# ESP32S31_RADIO register map
Vendor: Espressif; Series: ESP32-S31; File version: 3.52
Registers are 32-bit, read-write, no defined reset value unless marked. A register's access mark holds for its fields unless they carry their own. Offsets are from the block's base; [hi:lo] are bit positions; {n}, {i} and the like mark numbered series; 'fields as' and 'values as' point back to an identical list.

## BT_V3_2_CTE — Bluetooth direction-finding control words recovered from complete, independently named CTE accessors in the ESP32-S31 vendor baseband library. Only fields touched by those accessors are described; untouched bits remain unassigned.
Base 0x20102000
0x94 LC_8M_CONTROL — Project-assigned name. Bluetooth CTE LC 8-Mbit enable control.
  [0] LC_8M_ENABLE — Project-assigned name. The matched getter/setter pair reads and replaces bit 0.
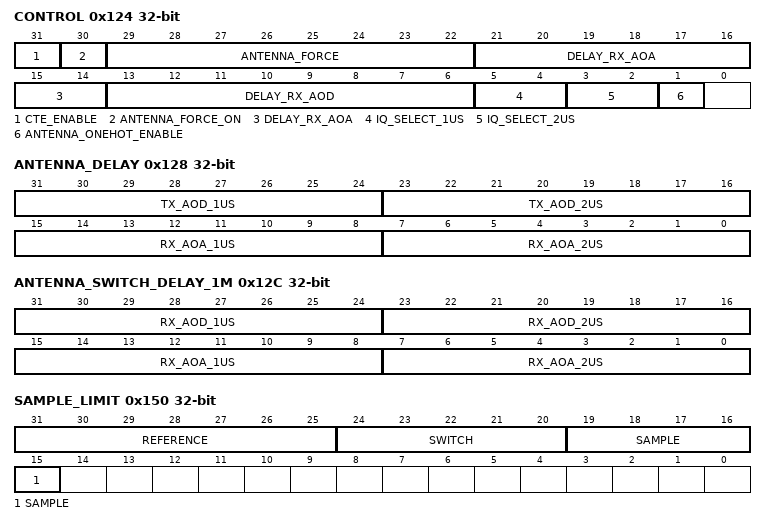
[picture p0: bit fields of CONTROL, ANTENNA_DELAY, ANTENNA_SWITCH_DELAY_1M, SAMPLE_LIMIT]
0x124 CONTROL — Project-assigned name. CTE antenna selection, receive-delay, IQ-selection and enable control. Bit 0 remains unassigned.
  [31] CTE_ENABLE — Project-assigned name. Complete ble_bb_cte_set_cte_en replaces bit 31 with the caller's Boolean image.
  [30] ANTENNA_FORCE_ON — Project-assigned name.
  [29:22] ANTENNA_FORCE — Project-assigned name.
  [21:14] DELAY_RX_AOA — Project-assigned name.
  [13:6] DELAY_RX_AOD — Project-assigned name.
  [5:4] IQ_SELECT_1US — Project-assigned name.
  [3:2] IQ_SELECT_2US — Project-assigned name.
  [1] ANTENNA_ONEHOT_ENABLE — Project-assigned name.
0x128 ANTENNA_DELAY — Project-assigned name. Four independent eight-bit antenna delays selected by CTE direction and slot duration.
  [31:24] TX_AOD_1US — Project-assigned name.
  [23:16] TX_AOD_2US — Project-assigned name.
  [15:8] RX_AOA_1US — Project-assigned name.
  [7:0] RX_AOA_2US — Project-assigned name.
0x12C ANTENNA_SWITCH_DELAY_1M — Project-assigned name. Four independent antenna-switch delays used by the ordinary CTE accessors.
  [31:24] RX_AOD_1US — Project-assigned name.
  [23:16] RX_AOD_2US — Project-assigned name.
  [15:8] RX_AOA_1US — Project-assigned name.
  [7:0] RX_AOA_2US — Project-assigned name.
{0x130+2i} ANTENNA_MAP_ENTRY{i} (i=0..15) 16-bit wo — Project-assigned name. First sixteen halfword slots of the indexed antenna-map window. The complete setter copies caller-provided halfwords from index zero up to its input count; sixteen slots are the exact finite effects recovered under the current analysis bound, not a claim that the hardware window ends here.
  [15:0] VALUE — Project-assigned name. Complete 16-bit antenna-map element; the encoding remains unknown.
0x150 SAMPLE_LIMIT — Project-assigned name. Three independently readable and writable CTE sampling-limit fields.
  [31:25] REFERENCE — Project-assigned name.
  [24:20] SWITCH — Project-assigned name.
  [19:15] SAMPLE — Project-assigned name.
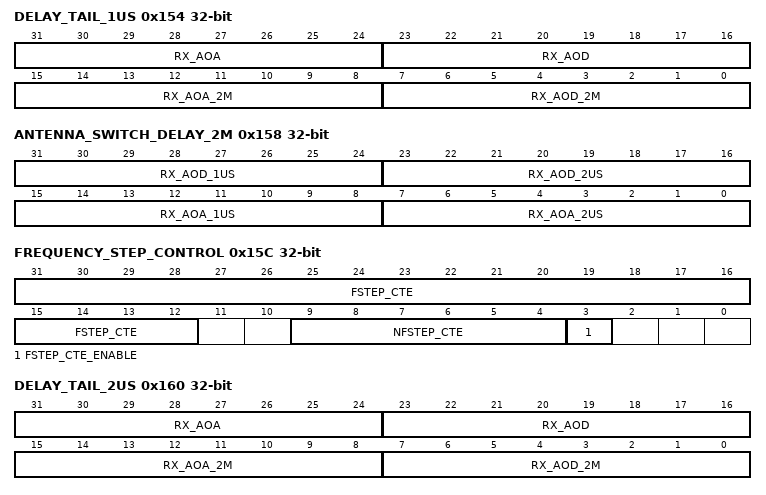
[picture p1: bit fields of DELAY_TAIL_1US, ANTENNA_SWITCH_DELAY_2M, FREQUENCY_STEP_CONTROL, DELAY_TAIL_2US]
0x154 DELAY_TAIL_1US — Project-assigned name. Four independent receive-tail delays for ordinary and 2-Mbit CTE operation with 1-microsecond slots.
  [31:24] RX_AOA — Project-assigned name.
  [23:16] RX_AOD — Project-assigned name.
  [15:8] RX_AOA_2M — Project-assigned name.
  [7:0] RX_AOD_2M — Project-assigned name.
0x158 ANTENNA_SWITCH_DELAY_2M — Project-assigned name. Four independent antenna-switch delays used by the explicit 2-Mbit CTE accessors.
  fields as ANTENNA_SWITCH_DELAY_1M
0x15C FREQUENCY_STEP_CONTROL — Project-assigned name. CTE frequency-step enable, count and 20-bit step image. Bits 0:2 and 10:11 remain unassigned.
  [31:12] FSTEP_CTE — Project-assigned name.
  [9:4] NFSTEP_CTE — Project-assigned name.
  [3] FSTEP_CTE_ENABLE — Project-assigned name.
0x160 DELAY_TAIL_2US — Project-assigned name. Four independent receive-tail delays for ordinary and 2-Mbit CTE operation with 2-microsecond slots.
  fields as DELAY_TAIL_1US
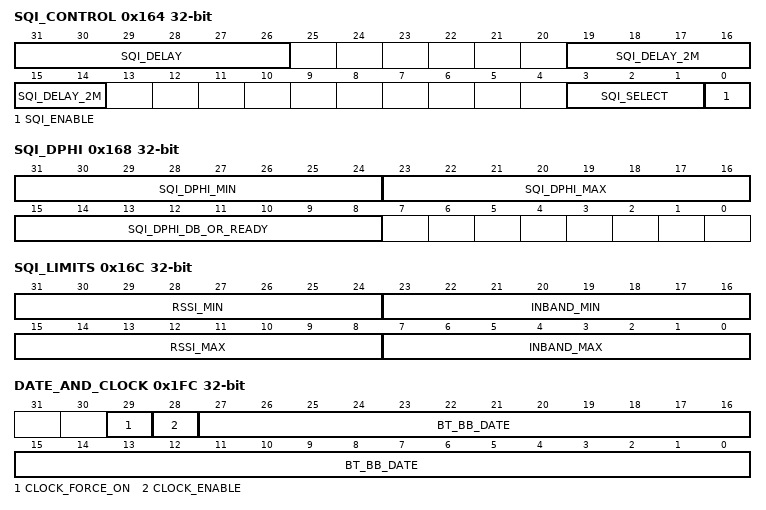
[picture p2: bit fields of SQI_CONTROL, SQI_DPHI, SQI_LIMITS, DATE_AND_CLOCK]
0x164 SQI_CONTROL — Project-assigned name. CTE signal-quality-indicator enable, selector and per-rate delay fields.
  [31:26] SQI_DELAY — Project-assigned name.
  [19:14] SQI_DELAY_2M — Project-assigned name.
  [3:1] SQI_SELECT — Project-assigned name.
  [0] SQI_ENABLE — Project-assigned name.
0x168 SQI_DPHI — Project-assigned name. CTE SQI phase-difference thresholds/status. The byte at bits 15:8 is exposed both as SQI_DPHI_DB and, independently, bit 14 as SQI_READY; the non-overlapping model preserves that exact alias in one combined field.
  [31:24] SQI_DPHI_MIN — Project-assigned name.
  [23:16] SQI_DPHI_MAX — Project-assigned name.
  [15:8] SQI_DPHI_DB_OR_READY — Project-assigned name. Eight-bit SQI_DPHI_DB image; bit 6 of this field is also the independently addressable SQI_READY bit.
0x16C SQI_LIMITS — Project-assigned name. Four independent eight-bit in-band and RSSI thresholds used by the CTE SQI logic.
  [31:24] RSSI_MIN — Project-assigned name.
  [23:16] INBAND_MIN — Project-assigned name.
  [15:8] RSSI_MAX — Project-assigned name.
  [7:0] INBAND_MAX — Project-assigned name.
0x1FC DATE_AND_CLOCK — Project-assigned name. Bluetooth baseband date image and CTE clock gates. Bits 31:30 remain unassigned.
  [29] CLOCK_FORCE_ON — Project-assigned name.
  [28] CLOCK_ENABLE — Project-assigned name.
  [27:0] BT_BB_DATE ro — Project-assigned name.
